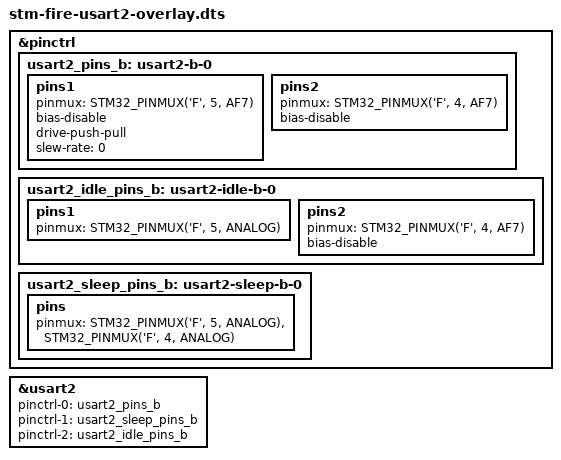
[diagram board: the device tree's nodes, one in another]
// SPDX-License-Identifier: (GPL-2.0+ OR BSD-3-Clause)
/*
 * Copyright (C) STMicroelectronics 2018 - All Rights Reserved
 * Author: Alexandre Torgue <alexandre.torgue@st.com>.
 */

/dts-v1/;
/plugin/;
#include <dt-bindings/pinctrl/stm32-pinfunc.h>
#include <dt-bindings/input/input.h>
#include <dt-bindings/mfd/st,stpmic1.h>

/{
	fragment@0 {
		target=<&pinctrl>;
		__overlay__ {
            usart2_pins_b: usart2-b-0 {
                pins1 {
                    pinmux = <STM32_PINMUX('F', 5, AF7)>; /* USART2_TX */
                    bias-disable;
                    drive-push-pull;
                    slew-rate = <0>;
                };
                pins2 {
                    pinmux = <STM32_PINMUX('F', 4, AF7)>; /* USART2_RX */
                    bias-disable;
                };
            };

            usart2_idle_pins_b: usart2-idle-b-0 {
                pins1 {
                    pinmux = <STM32_PINMUX('F', 5, ANALOG)>; /* USART2_TX */
                };
                pins2 {
                    pinmux = <STM32_PINMUX('F', 4, AF7)>; /* USART2_RX */
                    bias-disable;
                };
            };

            usart2_sleep_pins_b: usart2-sleep-b-0 {
                pins {
                    pinmux = <STM32_PINMUX('F', 5, ANALOG)>, /* USART2_TX */
                        <STM32_PINMUX('F', 4, ANALOG)>; /* USART2_RX */
                };
            };

        };
	};
	fragment@1 {
		target=<&usart2>;
		__overlay__ {
            pinctrl-names = "default", "sleep", "idle";
            pinctrl-0 = <&usart2_pins_b>;
            pinctrl-1 = <&usart2_sleep_pins_b>;
            pinctrl-2 = <&usart2_idle_pins_b>;
			status = "okay";
		};
	};

};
